VERSION "HIPBNYYYYYYYYYYYYYYYYYYYYYYYYYYYYYYYYYYYYY/4/%%%/4/'%**4YYY///"

NS_ :

BS_:

BU_: DBG VCU BMS MCM DCU DAQ S2C

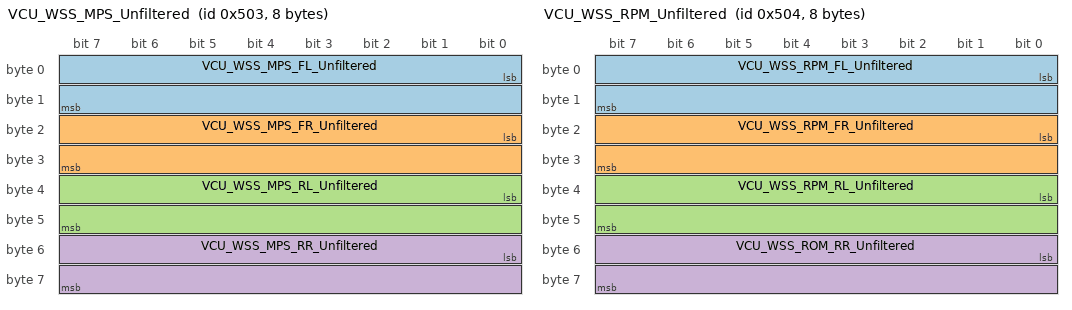
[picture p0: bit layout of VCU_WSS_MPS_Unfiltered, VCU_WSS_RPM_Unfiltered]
BO_ 1283 VCU_WSS_MPS_Unfiltered: 8 VCU
 SG_ VCU_WSS_MPS_FL_Unfiltered : 0|16@1+ (1,0) [0|32767] "MPS" VCU
 SG_ VCU_WSS_MPS_FR_Unfiltered : 16|16@1+ (1,0) [0|32767] "MPS" VCU
 SG_ VCU_WSS_MPS_RL_Unfiltered : 32|16@1+ (1,0) [0|32767] "MPS" VCU
 SG_ VCU_WSS_MPS_RR_Unfiltered : 48|16@1+ (1,0) [0|32767] "MPS" VCU

BO_ 1284 VCU_WSS_RPM_Unfiltered: 8 VCU
 SG_ VCU_WSS_RPM_FL_Unfiltered : 0|16@1+ (1,0) [0|32767] "RPM" VCU
 SG_ VCU_WSS_RPM_FR_Unfiltered : 16|16@1+ (1,0) [0|32767] "RPM" VCU
 SG_ VCU_WSS_RPM_RL_Unfiltered : 32|16@1+ (1,0) [0|32767] "RPM" VCU
 SG_ VCU_WSS_ROM_RR_Unfiltered : 48|16@1+ (1,0) [0|32767] "RPM" VCU

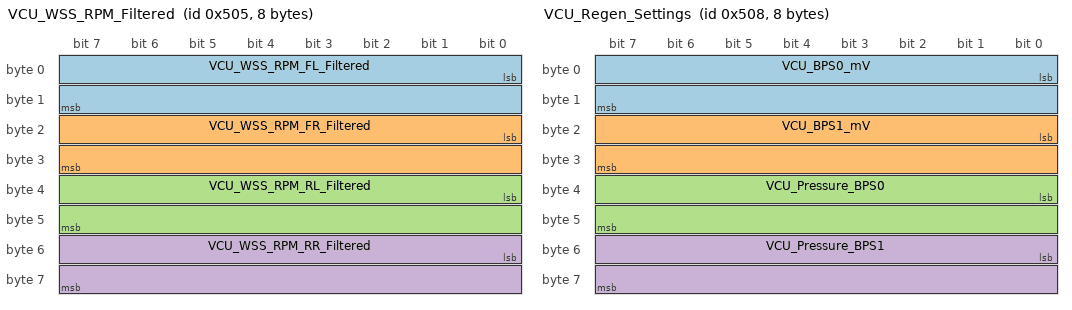
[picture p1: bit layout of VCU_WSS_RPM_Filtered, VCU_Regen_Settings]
BO_ 1285 VCU_WSS_RPM_Filtered: 8 VCU
 SG_ VCU_WSS_RPM_FL_Filtered : 0|16@1+ (1,0) [0|32767] "RPM" VCU
 SG_ VCU_WSS_RPM_FR_Filtered : 16|16@1+ (1,0) [0|32767] "RPM" VCU
 SG_ VCU_WSS_RPM_RL_Filtered : 32|16@1+ (1,0) [0|32767] "RPM" VCU
 SG_ VCU_WSS_RPM_RR_Filtered : 48|16@1+ (1,0) [0|32767] "RPM" VCU

BO_ 1288 VCU_Regen_Settings: 8 VCU
 SG_ VCU_BPS0_mV : 0|16@1+ (1,0) [0|65535] "mV" VCU
 SG_ VCU_BPS1_mV : 16|16@1+ (1,0) [0|65535] "mV" VCU
 SG_ VCU_Pressure_BPS0 : 32|16@1+ (1,0) [0|65535] "kPa" VCU
 SG_ VCU_Pressure_BPS1 : 48|16@1+ (1,0) [0|65535] "kPa" VCU

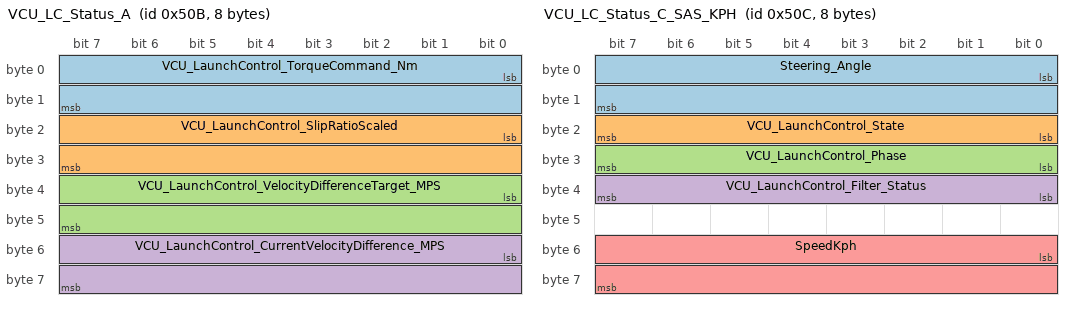
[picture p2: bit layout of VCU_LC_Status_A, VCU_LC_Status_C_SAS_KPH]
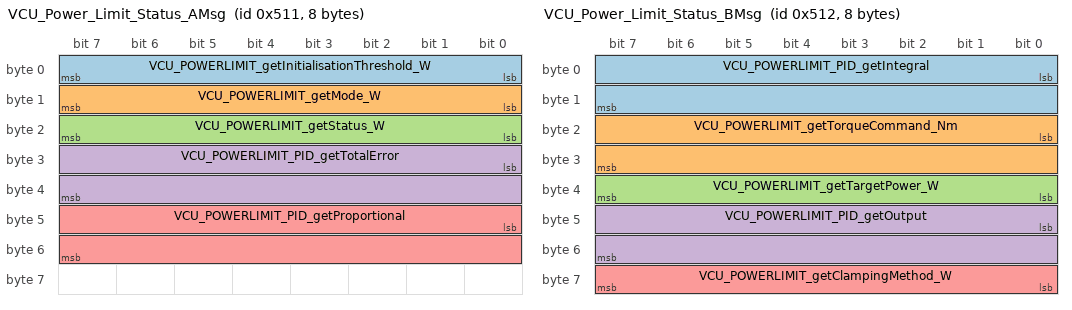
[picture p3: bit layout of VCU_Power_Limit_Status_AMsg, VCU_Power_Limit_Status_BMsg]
BO_ 1291 VCU_LC_Status_A: 8 VCU
 SG_ VCU_LaunchControl_TorqueCommand_Nm : 0|16@1- (1,0) [-32768|32767] "Nm" VCU
 SG_ VCU_LaunchControl_SlipRatioScaled : 16|16@1- (1,0) [-32768|32767] "" VCU
 SG_ VCU_LaunchControl_VelocityDifferenceTarget_MPS : 32|16@1- (1,0) [-32768|32767] "MPS" VCU
 SG_ VCU_LaunchControl_CurrentVelocityDifference_MPS : 48|16@1- (1,0) [-32768|32767] "MPS" VCU

BO_ 1292 VCU_LC_Status_C_SAS_KPH: 8 VCU
 SG_ Steering_Angle : 0|16@1- (1,0) [-100|100] "Degrees" VCU
 SG_ VCU_LaunchControl_State : 16|8@1+ (1,0) [0|255] "" VCU
 SG_ VCU_LaunchControl_Phase : 24|8@1+ (1,0) [0|255] "" VCU
 SG_ VCU_LaunchControl_Filter_Status : 32|8@1+ (1,0) [0|255] "" VCU
 SG_ SpeedKph : 48|16@1+ (1,0) [0|200] "km/h" mcm

 BO_ 1297 VCU_Power_Limit_Status_AMsg: 8 VCU
 SG_ VCU_POWERLIMIT_getInitialisationThreshold_W : 0|8@1+ (1,0) [0|255] "W" VCU
 SG_ VCU_POWERLIMIT_getMode_W : 8|8@1+ (1,0) [0|255] "W" VCU
 SG_ VCU_POWERLIMIT_getStatus_W : 16|8@1+ (1,0) [0|255] "W" VCU
 SG_ VCU_POWERLIMIT_PID_getTotalError : 24|16@1- (1,0) [-32768|32767] "" VCU
 SG_ VCU_POWERLIMIT_PID_getProportional : 40|16@1- (1,0) [-32768|32767] "" VCU

BO_ 1298 VCU_Power_Limit_Status_BMsg: 8 VCU
 SG_ VCU_POWERLIMIT_PID_getIntegral : 0|16@1- (1,0) [-32768|32767] "" VCU
 SG_ VCU_POWERLIMIT_getTorqueCommand_Nm : 16|16@1- (1,0) [-32768|32767] "Nm" VCU
 SG_ VCU_POWERLIMIT_getTargetPower_W : 32|8@1+ (1,0) [0|255] "W" VCU
 SG_ VCU_POWERLIMIT_PID_getOutput : 40|16@1- (1,0) [-32768|32767] "" VCU
 SG_ VCU_POWERLIMIT_getClampingMethod_W : 56|8@1+ (1,0) [0|255] "W" VCU

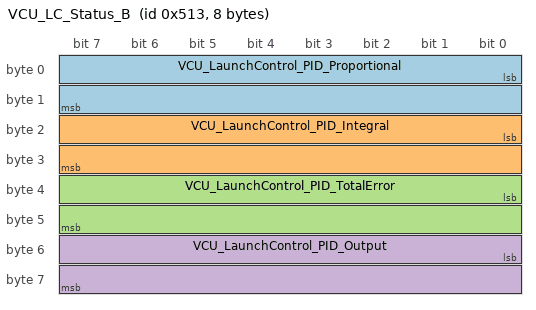
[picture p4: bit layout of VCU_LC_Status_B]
BO_ 1299 VCU_LC_Status_B: 8 VCU
 SG_ VCU_LaunchControl_PID_Proportional : 0|16@1- (1,0) [-32768|32767] "" VCU
 SG_ VCU_LaunchControl_PID_Integral : 16|16@1- (1,0) [-32768|32767] "" VCU
 SG_ VCU_LaunchControl_PID_TotalError : 32|16@1- (1,0) [-32768|32767] "" VCU
 SG_ VCU_LaunchControl_PID_Output : 48|16@1- (1,0) [-32768|32767] "" VCU

CM_ BU_ VCU "The vehicle control unit";
CM_ BU_ MCM "The motor controller of the car";
CM_ BU_ BMS "The battery management system";
CM_ BU_ DCU "The dash control unit";
CM_ BO_ 160 "Motor Controller Temperatures Set 1";
CM_ BO_ 161 "Motor Controller Temperatures Set 2";
CM_ BO_ 162 "Motor Controller Temperatures Set 3";
CM_ BO_ 165 "Motor Position Information";
CM_ BO_ 166 "Motor Current Information";
CM_ BO_ 167 "Motor Voltage Information";
CM_ BO_ 192 "Motor Controller Command Messages";
CM_ BO_ 1280 "Throttle Position Sensor 0 Value";
CM_ BO_ 1281 "Throttle Position Sensor 1 Value";
CM_ BO_ 1282 "Brake Pressure Sensor Value";
CM_ BO_ 1283 "Wheel Speed Sensor Value";
CM_ BO_ 1286 "VCU Safety Messages";
CM_ BO_ 1568 "BMS Status and Fault Message";
CM_ BO_ 1571 "Accumulator Pack Voltage and Current";
CM_ BO_ 1572 "Accumulator Load Voltage and Current";
CM_ BO_ 1573 "Cell Voltage High and Low";
CM_ BO_ 1574 "Cell Voltage Average and Mismatch";
CM_ BO_ 1575 "SOC Percentage and Battery Capacity";
CM_ BO_ 1576 "Cell and BMS Board Temperature Average";
CM_ BO_ 1577 "Cell Temperature High and Low";
CM_ BO_ 1584 "BMS Board Temperature High and Low";
CM_ BO_ 1585 "Accumulator Load Power";
CM_ BO_ 1793 "Dash Control Unit Timestamp";
CM_ BO_ 2023 "This CAN id is used for communication between the energy meter and the download tool.";
CM_ BO_ 2031 "This CAN id is used for communication between the energy meter and the download tool.";
CM_ BU_ BMS1000M "BMS Master Controller";
CM_ BU_ VCU "Vehicle Control Unit or Master System Controller";
CM_ BO_ 1536 "Sent when BMS state transition is needed";
CM_ BO_ 1538 "Sent every 100ms";
CM_ BO_ 1552 "Sent every 100ms";
CM_ BO_ 1553 "Sent every 100ms";
CM_ BO_ 1554 "Sent every 100ms";
CM_ BO_ 1568 "Sent every 100ms";
CM_ SG_ 1568 BMS_Pack_Current "Charging is positive";
CM_ BO_ 1569 "Sent every 100ms";
CM_ BO_ 1570 "Sent every 100ms";
CM_ BO_ 1571 "Sent every 100ms";
CM_ BO_ 1788 "Sent every 1 second";
CM_ BO_ 1788 "Sent every 1 second";
CM_ BO_ 1572 "Sent every 100ms";

BA_DEF_ "BusType" STRING ;
BA_DEF_ SG_ "FieldType" STRING ;

BA_DEF_DEF_ "BusType" "CAN";
BA_DEF_DEF_ "FieldType" "";

BA_ "FieldType" SG_ 100 DRIVER_HEARTBEAT_cmd "DRIVER_HEARTBEAT_cmd";

VAL_ 100 DRIVER_HEARTBEAT_cmd 2 "DRIVER_HEARTBEAT_cmd_REBOOT" 1 "DRIVER_HEARTBEAT_cmd_SYNC" 0 "DRIVER_HEARTBEAT_cmd_NOOP" ;
VAL_ 1024 CurrentGain 0 "x1" 1 "x2" 2 "x4" 3 "x8" 4 "x16" 5 "x32" ;
VAL_ 1024 Logging 0 "x1" 1 "x2" 2 "x4" 3 "x8" 4 "x16" 5 "x32" ;/Users/sean/Downloads/NLG5_BRUSA.dbc
VAL_ 1536 BMS_State_Request 0 "No State Change Requested" 1 "Request BMS Sleep" 2 "Request BMS Idle" 3 "Request BMS Pre-charge" 4 "Request Clear Faults" ;
VAL_ 1538 BMS_Imminent_Contactor_Opening_Warning 0 "Contactors will not open within 2 seconds" 1 "Contactors will open within 2 seconds due to fault condition" ;
VAL_ 1552 BMS_Current_State 0 "BMS Internal Error" 1 "BMS Sleep" 2 "BMS Startup" 3 "BMS Idle" 4 "BMS Pre-charge" 5 "BMS Active" 6 "BMS Fault" ;
